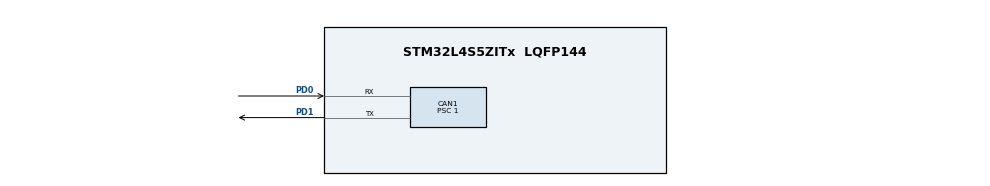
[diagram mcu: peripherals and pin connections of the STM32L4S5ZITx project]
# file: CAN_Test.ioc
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CAN1.BS1=CAN_BS1_3TQ
CAN1.BS2=CAN_BS2_4TQ
CAN1.CalculateBaudRate=500000
CAN1.CalculateTimeBit=2000
CAN1.CalculateTimeQuantum=250.0
CAN1.Prescaler=1
Mcu.Family=STM32L4
Mcu.Name=STM32L4S5ZITx
Mcu.Package=LQFP144
NVIC.PriorityGroup=NVIC_PRIORITYGROUP_4
PD0.Mode=CAN_Activate
PD0.Signal=CAN1_RX
PD1.Mode=CAN_Activate
PD1.Signal=CAN1_TX
ProjectManager.HeapSize=0x200
ProjectManager.StackSize=0x400
ProjectManager.TargetToolchain=STM32CubeIDE
RCC.HSE_VALUE=8000000
RCC.HSI48_VALUE=48000000
RCC.HSI_VALUE=16000000
RCC.LSE_VALUE=32768
RCC.MSI_VALUE=4000000
RCC.VCOOutputFreq_Value=32000000
board=custom

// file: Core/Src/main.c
/* USER CODE BEGIN Header */
/**
  ******************************************************************************
  * @file           : main.c
  * @brief          : Main program body
  ******************************************************************************
  * @attention
  *
  * Copyright (c) 2023 STMicroelectronics.
  * All rights reserved.
  *
  * This software is licensed under terms that can be found in the LICENSE file
  * in the root directory of this software component.
  * If no LICENSE file comes with this software, it is provided AS-IS.
  *
  ******************************************************************************
  */
/* USER CODE END Header */
#include "main.h"

CAN_HandleTypeDef hcan1;
CAN_FilterTypeDef sFilterConfig;
CAN_TxHeaderTypeDef TxHeader; //will be used to store the header information, like RTR, DLC
CAN_RxHeaderTypeDef RxHeader;
uint8_t TxData[8];
uint32_t TxMailbox;

void SystemClock_Config(void);
static void MX_GPIO_Init(void);
static void MX_CAN1_Init(void);

int main(void)
{

  /* MCU Configuration--------------------------------------------------------*/

  /* Reset of all peripherals, Initializes the Flash interface and the Systick. */
  HAL_Init();

  /* Configure the system clock */
  SystemClock_Config();

  /* Initialize all configured peripherals */
  MX_GPIO_Init();
  MX_CAN1_Init(); //includes init and filter and start
  /* USER CODE BEGIN 2 */

  if(HAL_CAN_IsSleepActive(&hcan1))
  {
	  HAL_CAN_WakeUp(&hcan1);
	  HAL_CAN_Start(&hcan1);
  }

  /* USER CODE END 2 */

  // store the required values in the TxHeader, and in the TxData

  //TxHeader.ExtId =CAN_ID_EXT;
  TxHeader.IDE = CAN_ID_STD; //Standard ID or Extended ID
  TxHeader.StdId = 0x446;	//is the Identifier ( ID of the Transmitter, and it should be maximum 11 bit wide)
  TxHeader.RTR = CAN_RTR_DATA; //indicates that we are sending a data frame
  TxHeader.DLC = 8;	//8 Bytes of data Field
  //TxHeader.TransmitGlobalTime =DISABLE;

  TxData[0] = 0x01;	//Start of message
  TxData[1] = 0xAA; //Board ID to talk
  TxData[2] = 0x00; //Read / Write Command
  TxData[3] = 0x01; //Data length
  TxData[4] = 0xAA; //Data Byte 0
  TxData[5] = 0xAA; //Data Byte 1
  TxData[6] = 0xAA; //Data Byte 2
  TxData[7] = 0x04; // End Of message

  /* Infinite loop */
  while (1)
  {

	 	 memset(CANRxData, 0x00, sizeof(CANRxData));
	 	 memset(CANTxData, 0x00, sizeof(CANTxData));

	 	  // test relay
	 	  HAL_GPIO_WritePin(GPIOG,GPIO_PIN_8,GPIO_PIN_SET);
	 	  HAL_Delay (100);
	 	  HAL_GPIO_WritePin(GPIOG,GPIO_PIN_8,GPIO_PIN_RESET);

	 	  //Sent Message to CAN network

	 	 HAL_CAN_AddTxMessage(&hcan1, &TxHeader, TxData, &TxMailbox);
	 	//if (HAL_CAN_GetTxMailboxesFreeLevel(&hcan1)!=1)
	 	//if (HAL_CAN_IsTxMessagePending(&hcan1,TxMailbox))

	 	 //Listen to CAN network

	 	 uint8_t res=1;
	 	while(1){
	 	res = HAL_CAN_GetRxMessage(&hcan1, CAN_RX_FIFO0, &RxHeader, CANRxData);
	 	if (res==HAL_OK) break;
	 	}

  }
}

void SystemClock_Config(void)
{
  RCC_OscInitTypeDef RCC_OscInitStruct = {0};
  RCC_ClkInitTypeDef RCC_ClkInitStruct = {0};

  /** Configure the main internal regulator output voltage
  */
  if (HAL_PWREx_ControlVoltageScaling(PWR_REGULATOR_VOLTAGE_SCALE1) != HAL_OK)
  {
    Error_Handler();
  }

  /** Initializes the RCC Oscillators according to the specified parameters
  * in the RCC_OscInitTypeDef structure.
  */
  RCC_OscInitStruct.OscillatorType = RCC_OSCILLATORTYPE_MSI;
  RCC_OscInitStruct.MSIState = RCC_MSI_ON;
  RCC_OscInitStruct.MSICalibrationValue = 0;
  RCC_OscInitStruct.MSIClockRange = RCC_MSIRANGE_6;
  RCC_OscInitStruct.PLL.PLLState = RCC_PLL_NONE;
  if (HAL_RCC_OscConfig(&RCC_OscInitStruct) != HAL_OK)
  {
    Error_Handler();
  }

  /** Initializes the CPU, AHB and APB buses clocks
  */
  RCC_ClkInitStruct.ClockType = RCC_CLOCKTYPE_HCLK|RCC_CLOCKTYPE_SYSCLK
                              |RCC_CLOCKTYPE_PCLK1|RCC_CLOCKTYPE_PCLK2;
  RCC_ClkInitStruct.SYSCLKSource = RCC_SYSCLKSOURCE_MSI;
  RCC_ClkInitStruct.AHBCLKDivider = RCC_SYSCLK_DIV1;
  RCC_ClkInitStruct.APB1CLKDivider = RCC_HCLK_DIV1;
  RCC_ClkInitStruct.APB2CLKDivider = RCC_HCLK_DIV1;

  if (HAL_RCC_ClockConfig(&RCC_ClkInitStruct, FLASH_LATENCY_0) != HAL_OK)
  {
    Error_Handler();
  }
}

static void MX_CAN1_Init(void)
{

  hcan1.Instance = CAN1;
  hcan1.Init.Prescaler = 1;
  hcan1.Init.Mode = CAN_MODE_NORMAL;
  hcan1.Init.SyncJumpWidth = CAN_SJW_1TQ;
  hcan1.Init.TimeSeg1 = CAN_BS1_3TQ;
  hcan1.Init.TimeSeg2 = CAN_BS2_4TQ;
  hcan1.Init.TimeTriggeredMode = DISABLE;
  hcan1.Init.AutoBusOff = DISABLE;
  hcan1.Init.AutoWakeUp = DISABLE;
  hcan1.Init.AutoRetransmission = DISABLE;
  hcan1.Init.ReceiveFifoLocked = DISABLE;
  hcan1.Init.TransmitFifoPriority = DISABLE;
  if (HAL_CAN_Init(&hcan1) != HAL_OK)
  {
    Error_Handler();
  }

  /* USER CODE BEGIN CAN1_Init 2 */

	sFilterConfig.FilterActivation = CAN_FILTER_ENABLE;
	sFilterConfig.FilterBank=13; 							// max is 28
	sFilterConfig.FilterFIFOAssignment=CAN_FILTER_FIFO0; 	//fifo0 or fifo1
	sFilterConfig.FilterIdLow = 0x10;
	sFilterConfig.FilterIdHigh = 0x446<<5; 					//The value set in this register will be compared to the incoming Identifier: higher 16 bits of ID register , to only compare the STD ID of the incoming message, shift the value by 5. The STD ID starts from 5th bit in the ID HIGH Register
	sFilterConfig.FilterMaskIdHigh=0x446<<5; 				//Higher 16 Bits of the MASK register. The value set in this register will enable the comparison of that particular bit in the ID register to that of the incoming ID.
	sFilterConfig.FilterMaskIdLow=0;
	sFilterConfig.FilterMode=CAN_FILTERMODE_IDMASK; 		//mask mode or list mode
	sFilterConfig.FilterScale=CAN_FILTERSCALE_32BIT; 		// 2,16 or 32 bit filter registers
	sFilterConfig.SlaveStartFilterBank=28;

	if(HAL_CAN_ConfigFilter(&hcan1, &sFilterConfig)!=HAL_OK)
	{
		Error_Handler();
	}
	if(HAL_CAN_Start(&hcan1) != HAL_OK)
	{
		Error_Handler();
	}

  /* USER CODE END CAN1_Init 2 */

}

static void MX_GPIO_Init(void)
{

  /* GPIO Ports Clock Enable */
  __HAL_RCC_GPIOD_CLK_ENABLE();

}

void Error_Handler(void)
{
  __disable_irq();
  while (1)
  {
  }
}
